NS_ :

BS_:

BO_ 928 EPB_STATUS: 8 XXX
 SG_ EPB_BRAKE : 16|1@1+ (1,0) [0|3] "" XXX

BO_ 1104 SEATBELT_STATUS: 8 XXX
 SG_ DRIVER_SEAT_BELT_ONOFF : 21|1@0+ (1,0) [0|3] "" XXX

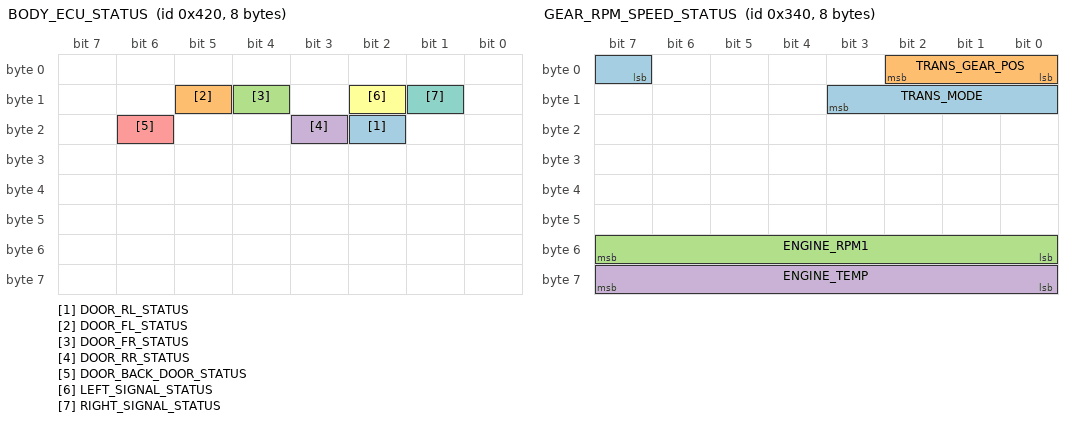
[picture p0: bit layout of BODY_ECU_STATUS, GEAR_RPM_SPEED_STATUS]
BO_ 1056 BODY_ECU_STATUS: 8 XXX
 SG_ DOOR_RL_STATUS : 18|1@0+ (1,0) [0|255] "" XXX
 SG_ DOOR_FL_STATUS : 13|1@0+ (1,0) [0|1] "" XXX
 SG_ DOOR_FR_STATUS : 12|1@0+ (1,0) [0|1] "" XXX
 SG_ DOOR_RR_STATUS : 19|1@0+ (1,0) [0|1] "" XXX
 SG_ DOOR_BACK_DOOR_STATUS : 22|1@0+ (1,0) [0|1] "" XXX
 SG_ LEFT_SIGNAL_STATUS : 10|1@0+ (1,0) [0|1] "" XXX
 SG_ RIGHT_SIGNAL_STATUS : 9|1@0+ (1,0) [0|1] "" XXX

BO_ 832 GEAR_RPM_SPEED_STATUS: 8 XXX
 SG_ TRANS_MODE : 7|5@1+ (1,0) [0|0] "" XXX
 SG_ TRANS_GEAR_POS : 2|3@0+ (1,0) [0|1] "" XXX
 SG_ ENGINE_RPM1 : 55|8@0+ (1,0) [0|255] "" XXX
 SG_ ENGINE_TEMP : 63|8@0+ (1,0) [0|255] "" XXX

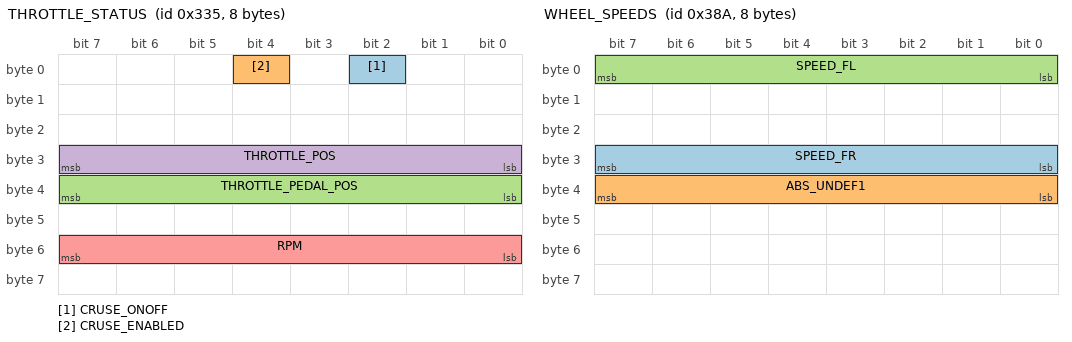
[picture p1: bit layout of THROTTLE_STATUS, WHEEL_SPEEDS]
BO_ 821 THROTTLE_STATUS: 8 XXX
 SG_ CRUSE_ONOFF : 2|1@0+ (1,0) [0|1] "on/off" XXX
 SG_ CRUSE_ENABLED : 4|1@0+ (1,0) [0|1] "" XXX
 SG_ THROTTLE_PEDAL_POS : 32|8@1+ (1,0) [0|255] "" XXX
 SG_ THROTTLE_POS : 24|8@1+ (1,0) [0|255] "" XXX
 SG_ RPM : 48|8@1- (1,0) [0|65535] "" XXX

BO_ 922 STEERING_ANGLE_STATUS: 8 XXX
 SG_ STEER_ANGLE_9000 : 7|16@0- (1,0) [0|65535] "" XXX

BO_ 906 WHEEL_SPEEDS: 8 XXX
 SG_ SPEED_FR : 24|8@1+ (1,0) [0|255] "" XXX
 SG_ ABS_UNDEF1 : 32|8@1+ (1,0) [0|255] "" XXX
 SG_ SPEED_FL : 0|8@1+ (1,0) [0|255] "" XXX

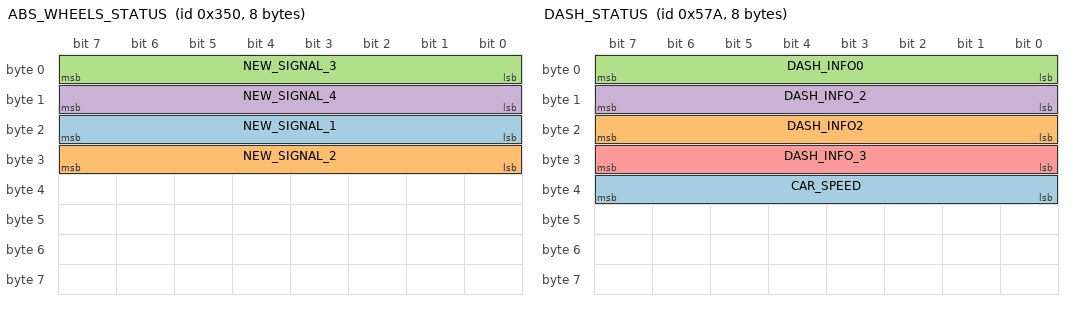
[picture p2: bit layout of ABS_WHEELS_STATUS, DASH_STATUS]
BO_ 848 ABS_WHEELS_STATUS: 8 XXX
 SG_ NEW_SIGNAL_1 : 23|8@0+ (1,0) [0|255] "" XXX
 SG_ NEW_SIGNAL_2 : 31|8@0+ (1,0) [0|255] "" XXX
 SG_ NEW_SIGNAL_3 : 7|8@0+ (1,0) [0|255] "" XXX
 SG_ NEW_SIGNAL_4 : 15|8@0+ (1,0) [0|255] "" XXX

BO_ 1402 DASH_STATUS: 8 XXX
 SG_ CAR_SPEED : 32|8@1+ (1,0) [0|255] "" XXX
 SG_ DASH_INFO2 : 16|8@1+ (1,0) [0|255] "" XXX
 SG_ DASH_INFO0 : 0|8@1+ (1,0) [0|255] "" XXX
 SG_ DASH_INFO_2 : 15|8@0+ (1,0) [0|255] "" XXX
 SG_ DASH_INFO_3 : 31|8@0+ (1,0) [0|255] "" XXX

BO_ 1306 _SPEEDX: 8 XXX
 SG_ DASH_CAR_SPEED : 7|9@0+ (1,0) [0|255] "" XXX

BO_ 1296 undefined: 8 XXX

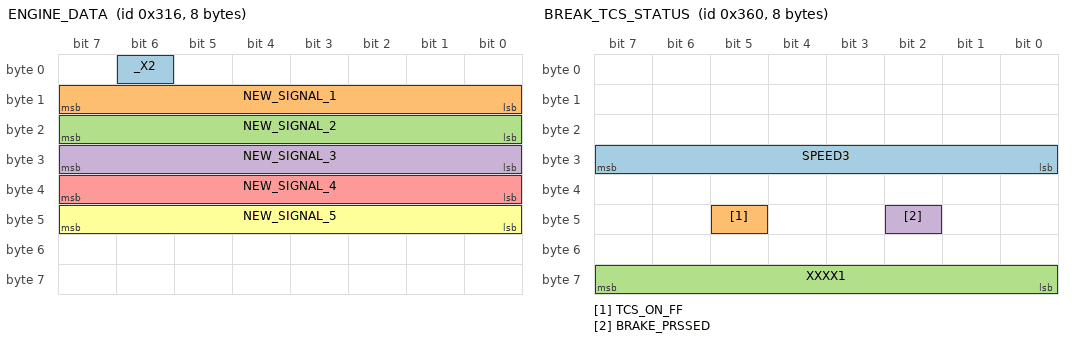
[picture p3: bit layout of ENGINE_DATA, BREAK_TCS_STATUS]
BO_ 790 ENGINE_DATA: 8 XXX
 SG_ _X2 : 6|1@0+ (1,0) [0|1] "" XXX
 SG_ NEW_SIGNAL_1 : 15|8@0+ (1,0) [0|255] "" XXX
 SG_ NEW_SIGNAL_2 : 23|8@0+ (1,0) [0|255] "" XXX
 SG_ NEW_SIGNAL_3 : 31|8@0+ (1,0) [0|255] "" XXX
 SG_ NEW_SIGNAL_4 : 39|8@0+ (1,0) [0|255] "" XXX
 SG_ NEW_SIGNAL_5 : 47|8@0+ (1,0) [0|255] "" XXX

BO_ 1313 undefined_2: 8 XXX

BO_ 1312 __trigger_every_range: 8 XXX
 SG_ __SIGNAL_every_interval : 4|1@0+ (1,0) [0|1] "" XXX

BO_ 896 undefined_3: 8 XXX
 SG_ NEW_SIGNAL_1 : 32|4@1+ (1,0) [0|15] "" XXX

BO_ 809 undefined_4: 8 XXX

BO_ 864 BREAK_TCS_STATUS: 8 XXX
 SG_ SPEED3 : 24|8@1+ (1,0) [0|255] "" XXX
 SG_ TCS_ON_FF : 45|1@0+ (1,0) [0|1] "" XXX
 SG_ XXXX1 : 63|8@0+ (1,0) [0|255] "" XXX
 SG_ BRAKE_PRSSED : 42|1@0+ (1,0) [0|1] "" XXX

BO_ 842 undefined_5: 8 XXX

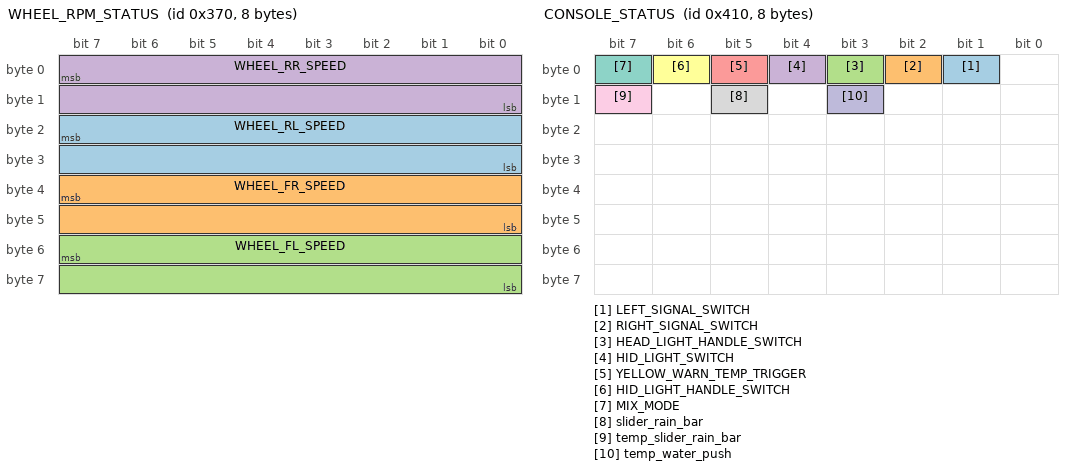
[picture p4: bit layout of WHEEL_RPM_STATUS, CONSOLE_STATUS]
BO_ 880 WHEEL_RPM_STATUS: 8 XXX
 SG_ WHEEL_RL_SPEED : 23|16@0+ (1,0) [0|255] "" XXX
 SG_ WHEEL_FR_SPEED : 39|16@0+ (1,0) [0|255] "" XXX
 SG_ WHEEL_FL_SPEED : 55|16@0+ (1,0) [0|255] "" XXX
 SG_ WHEEL_RR_SPEED : 7|16@0- (1,0) [0|255] "" XXX

BO_ 1040 CONSOLE_STATUS: 8 XXX
 SG_ LEFT_SIGNAL_SWITCH : 1|1@0+ (1,0) [0|1] "" XXX
 SG_ RIGHT_SIGNAL_SWITCH : 2|1@0+ (1,0) [0|1] "" XXX
 SG_ HEAD_LIGHT_HANDLE_SWITCH : 3|1@0+ (1,0) [0|1] "" XXX
 SG_ HID_LIGHT_SWITCH : 4|1@0+ (1,0) [0|1] "" XXX
 SG_ YELLOW_WARN_TEMP_TRIGGER : 5|1@0+ (1,0) [0|1] "" XXX
 SG_ HID_LIGHT_HANDLE_SWITCH : 6|1@0+ (1,0) [0|1] "" XXX
 SG_ MIX_MODE : 7|1@0+ (1,0) [0|1] "" XXX
 SG_ slider_rain_bar : 13|1@0+ (1,0) [0|1] "" XXX
 SG_ temp_slider_rain_bar : 15|1@0+ (1,0) [0|1] "" XXX
 SG_ temp_water_push : 11|1@0+ (1,0) [0|1] "" XXX

BO_ 1120 HAVC_STATUS: 8 XXX
 SG_ HAVC_TEMP : 32|8@1+ (1,0) [0|255] "" XXX

CM_ "AUTOGENERATED FILE, DO NOT EDIT";

CM_ "Imported file _honda_common.dbc starts here";
CM_ SG_ 304 "Seems to be platform-agnostic";
CM_ SG_ 316 "Should exist on Nidec";
CM_ SG_ 420 BRAKE_HOLD_RELATED "On when Brake Hold engaged";
CM_ SG_ 490 LONG_ACCEL "wheel speed derivative, noisy and zero snapping";
CM_ SG_ 773 PASS_AIRBAG_ON "Might just be indicator light";
CM_ SG_ 773 PASS_AIRBAG_OFF "Might just be indicator light";
CM_ SG_ 780 CRUISE_SPEED "255 = no speed";
CM_ SG_ 780 PCM_SPEED "Used by Nidec";
CM_ SG_ 780 PCM_GAS "Used by Nidec";
CM_ SG_ 804 CRUISE_SPEED_PCM "255 = no speed";

CM_ "Imported file _bosch_2018.dbc starts here";
CM_ SG_ 450 EPB_STATE "3: On, 2: Disengaging, 1: Engaging, 0: Off";
CM_ SG_ 576 LINE_DISTANCE_VISIBLE "Length of line visible, undecoded";
CM_ SG_ 577 LINE_FAR_EDGE_POSITION "Appears to be a measure of line thickness, indicates location of the portion of the line furthest from the car, undecoded";
CM_ SG_ 577 LINE_PARAMETER "Unclear if this is low quality line curvature rate or if this is something else, but it is correlated with line curvature, undecoded";
CM_ SG_ 577 LINE_DASHED "1 = line is dashed";
CM_ SG_ 577 LINE_SOLID "1 = line is solid";

CM_ "Imported file _bosch_adas_2018.dbc starts here";
CM_ SG_ 479 CONTROL_ON "Set to 5 when car is being controlled";
CM_ SG_ 479 AEB_STATUS "set for the duration of AEB event";
CM_ SG_ 479 AEB_BRAKING "set when braking is commanded during AEB event";
CM_ SG_ 479 AEB_PREPARE "set 1s before AEB";
CM_ SG_ 829 BEEP "beeps are pleasant, chimes are for warnngs etc...";

CM_ "Imported file _steering_sensors_a.dbc starts here";
CM_ "honda_accord_2018_can.dbc starts here";

VAL_ 1228 PROPILOT_NA_MSGS 0 "NO_MSG" 1 "NA_FRONT_CAMERA_IMPARED" 2 "STEERING_ASSIST_ON_STANDBY" 3 "NA_PARKING_ASSIST_ENABLED" 4 "STEER_ASSIST_CURRENTLY_NA" 5 "NA_BAD_WEATHER" 6 "NA_PARK_BRAKE_ON" 7 "NA_SEATBELT_NOT_FASTENED" ;
VAL_ 1228 BOTTOM_MSG 0 "OK_STEER_ASSIST_SETTINGS" 1 "NO_MSG" 2 "PRESS_SET_TO_SET_SPEED" 3 "PRESS_RES_SET_TO_CHANGE_SPEED" 4 "PRESS_RES_TO_RESTART" 5 "NO_MSG" 6 "CRUISE_NOT_AVAIL" 7 "NO_MSG" ;
VAL_ 689 FOLLOW_DISTANCE 0 "NO_FOLLOW_DISTANCE" 1 "FOLLOW_DISTANCE_1" 2 "FOLLOW_DISTANCE_2" 3 "FOLLOW_DISANCE_3" ;
VAL_ 689 AUDIBLE_TONE 0 "NO_TONE" 1 "CONT" 2 "FAST_BEEP_CONT" 3 "TRIPLE_FAST_BEEP_CONT" 4 "SLOW_BEEP_CONT" 5 "QUAD_SLOW_BEEP_CONT" 6 "SINGLE_BEEP_ONCE" 7 "DOUBLE_BEEP_ONCE" ;
VAL_ 689 SMALL_STEERING_WHEEL_ICON 0 "NO_ICON" 1 "GRAY_ICON" 2 "GRAY_ICON_FLASHING" 3 "GREEN_ICON" 4 "GREEN_ICON_FLASHING" 5 "RED_ICON" 6 "RED_ICON_FLASHING" 7 "YELLOW_ICON" ;
VAL_ 689 LARGE_STEERING_WHEEL_ICON 0 "NO_STEERINGWHEEL" 1 "GRAY_STEERINGWHEEL" 2 "GREEN_STEERINGWHEEL" 3 "GREEN_STEERINGWHEEL_FLASHING" ;
